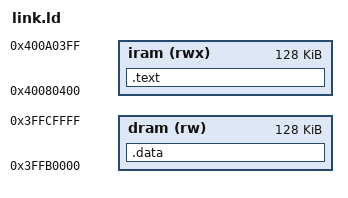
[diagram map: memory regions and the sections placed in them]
/* Раскладка для ESP32. Две области, и разница между ними не косметическая.
 *
 * iram это память для команд. Читать оттуда по одному байту нельзя:
 * шина отдаёт только выровненные слова, и l8ui по адресу в iram
 * снимает процессор в исключение. Поэтому строка идёт в dram.
 *
 * .literal обязан лежать ПЕРЕД кодом и близко: команда l32r умеет
 * читать только назад и не дальше чем на 256 КБ.
 */

MEMORY
{
    iram (rwx) : ORIGIN = 0x40080400, LENGTH = 0x20000
    dram (rw)  : ORIGIN = 0x3FFB0000, LENGTH = 0x20000
}

ENTRY(_start)

SECTIONS
{
    .text :
    {
        *(.literal .literal.*)
        *(.text .text.*)
    } > iram

    .data :
    {
        *(.rodata .rodata.*)
        *(.data .data.*)
    } > dram
}
